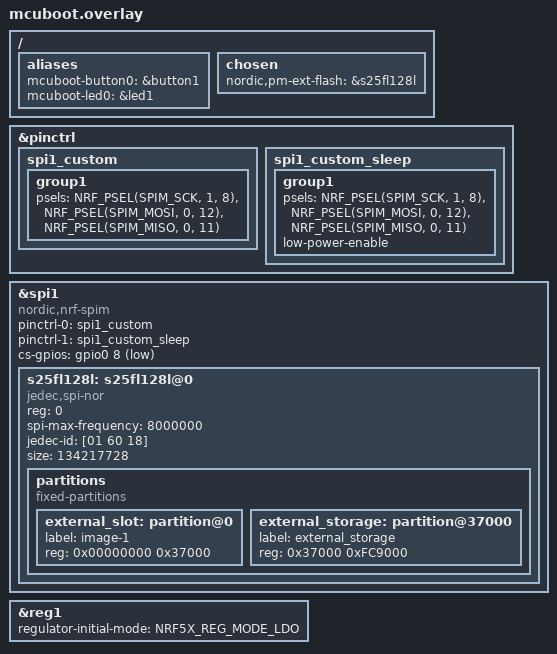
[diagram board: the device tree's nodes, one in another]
/ {
  aliases {
		mcuboot-button0 = &button1;
		mcuboot-led0 = &led1;
  };
};

/* Step 2.2 - Add external flash to MCUboot */
/* Custom pinctrl for MCUboot (same as application) */
&pinctrl {
/* uart0_default: uart0_default {
        group1 {
            psels = <NRF_PSEL(UART_TX, 0, 10)>,
                   <NRF_PSEL(UART_RTS, 0, 5)>;
        };
        group2 {
            psels = <NRF_PSEL(UART_RX, 0, 21)>,
                   <NRF_PSEL(UART_CTS, 0, 7)>;
            bias-pull-up;
        };
    };
    
    uart0_sleep: uart0_sleep {
        group1 {
            psels = <NRF_PSEL(UART_TX, 0, 10)>,
                   <NRF_PSEL(UART_RX, 0, 21)>,
                   <NRF_PSEL(UART_RTS, 0, 5)>,
                   <NRF_PSEL(UART_CTS, 0, 7)>;
            low-power-enable;
        };
    }; */

    spi1_custom: spi1_custom {
        group1 {
            psels = <NRF_PSEL(SPIM_SCK, 1, 8)>,
                   <NRF_PSEL(SPIM_MOSI, 0, 12)>,
                   <NRF_PSEL(SPIM_MISO, 0, 11)>;
        };
    };
    
    spi1_custom_sleep: spi1_custom_sleep {
        group1 {
            psels = <NRF_PSEL(SPIM_SCK, 1, 8)>,
                   <NRF_PSEL(SPIM_MOSI, 0, 12)>,
                   <NRF_PSEL(SPIM_MISO, 0, 11)>;
            low-power-enable;
        };
    };
};

/* Define the same S25FL128L flash device for MCUboot */
&spi1 {
    compatible = "nordic,nrf-spim";     
    status = "okay";
    pinctrl-0 = <&spi1_custom>;
    pinctrl-1 = <&spi1_custom_sleep>;
    pinctrl-names = "default", "sleep";
    cs-gpios = <&gpio0 8 GPIO_ACTIVE_LOW>;

    s25fl128l: s25fl128l@0 {
        compatible = "jedec,spi-nor";
        reg = <0>;
        spi-max-frequency = <8000000>;
        jedec-id = [01 60 18];
        size = <134217728>; /* 128 Mbit = 16 MB */
        status = "okay";

        // DEFINIR particiones SOLO una vez, aquí
        partitions {
            compatible = "fixed-partitions";
            #address-cells = <1>;
            #size-cells = <1>;

            // CRÍTICO: Slot secundario para MCUboot
            external_slot: partition@0 {
                label = "image-1";          // ← MCUboot busca esta etiqueta
                reg = <0x00000000 0x37000>; // 220KB
            };
            
            // Almacenamiento adicional
            external_storage: partition@37000 {
                label = "external_storage";
                reg = <0x37000 0xFC9000>;   // ~15.8MB
            };
        };
    };
};



/* Enable the flash for MCUboot use */
 &s25fl128l {
    status = "okay";
}; 


/* Tell Nordic Partition Manager about external flash for MCUboot */
/ {
    chosen {
        nordic,pm-ext-flash = &s25fl128l; 
    };
};

&reg1 {
    regulator-initial-mode = <NRF5X_REG_MODE_LDO>;
};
